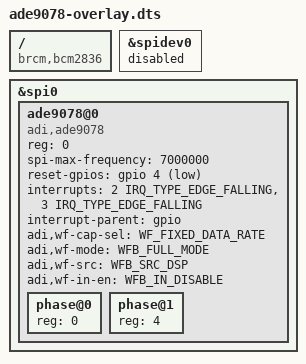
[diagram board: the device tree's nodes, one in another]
// SPDX-License-Identifier: GPL-2.0
/dts-v1/;
/plugin/;

#include <dt-bindings/gpio/gpio.h>
#include <dt-bindings/interrupt-controller/irq.h>
#include <dt-bindings/iio/meter/adi,ade9078.h>

/ {
    compatible = "brcm,bcm2836", "brcm,bcm2835";
    fragment@0 {
        target = <&spidev0>;
        __overlay__ {
            status = "disabled";
        };
    };
    fragment@1 {
        target = <&spi0>;
            __overlay__ {
            #address-cells = <1>;
            #size-cells = <0>;
            status = "okay";
            ade9078@0 {
                compatible = "adi,ade9078";
                reg = <0>;
                spi-max-frequency = <7000000>;
                
                #address-cells = <1>;
        	#size-cells = <0>;
        	reset-gpios = <&gpio 4 GPIO_ACTIVE_LOW>;
		interrupts = <2 IRQ_TYPE_EDGE_FALLING>, <3 IRQ_TYPE_EDGE_FALLING>;
		interrupt-names = "irq0", "irq1";
		interrupt-parent = <&gpio>;
		
		adi,wf-cap-sel = <WF_FIXED_DATA_RATE>;
		adi,wf-mode = <WFB_FULL_MODE>;
		adi,wf-src = <WFB_SRC_DSP>;
		adi,wf-in-en = <WFB_IN_DISABLE>;
		
		phase@0 {
		    reg = <0>;
		};
		phase@1 {
		    reg = <4>;
		};
            };
            };
        };
};
